AUTOSAR XML (schema 00051)
package /Components
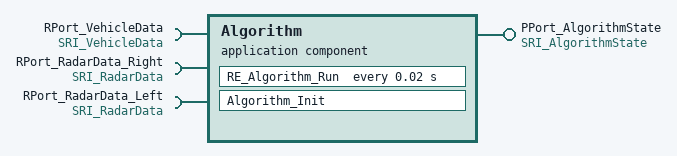
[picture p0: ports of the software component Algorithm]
  application sw component type Algorithm
    require port RPort_VehicleData: required-interface=SRI_VehicleData
      required-com-specs:
        data-element=TurnSignal_Status, init-value=SIGNAL_OK
        data-element=TurnSignal, init-value=TURN_OFF
        data-element=Vehicle_Speed, init-value=0
        data-element=Speed_Status, init-value=SIGNAL_OK
        data-element=Steering_Status, init-value=SIGNAL_OK
        data-element=Steering_Angle, init-value=0
        data-element=Gear_Status, init-value=SIGNAL_OK
        data-element=Gear, init-value=GEAR_PARK
    require port RPort_RadarData_Right: required-com-specs=[{data-element=Status, init-value=RADAR_OK}, {data-element=Distance, init-value=0}], required-interface=SRI_RadarData
    require port RPort_RadarData_Left: required-com-specs=[{data-element=Status, init-value=RADAR_OK}, {data-element=Distance, init-value=0}], required-interface=SRI_RadarData
    provide port PPort_AlgorithmState: provided-interface=SRI_AlgorithmState
      provided-com-specs:
        data-element=BSD_State_Right, init-value=BSD_CLEAR
        data-element=BSD_State_Left, init-value=BSD_CLEAR
    behavior Algorithm_IB: data-type-mapping=bsdDataTypeMappingsSet, handle-termination-and-restart=NO-SUPPORT
      timing event TE_Algorithm_20ms: start-on-event=RE_Algorithm_Run, period=0.02
      runnable Algorithm_Init
      runnable RE_Algorithm_Run
        data-read-access:
          6 x access:
            IN_RPort_RadarData_Right_Status: accessed-variable=RPort_RadarData_Right.Status
            IN_RPort_VehicleData_Speed_Status: accessed-variable=RPort_VehicleData.Speed_Status
            IN_RPort_RadarData_Right_Distance: accessed-variable=RPort_RadarData_Right.Distance
            IN_RPort_RadarData_Left_Distance: accessed-variable=RPort_RadarData_Left.Distance
            IN_RPort_RadarData_Left_Status: accessed-variable=RPort_RadarData_Left.Status
            IN_RPort_VehicleData_Vehicle_Speed: accessed-variable=RPort_VehicleData.Vehicle_Speed
        data-write-access:
          access OUT_PPort_AlgorithmState_BSD_State_Right: accessed-variable=PPort_AlgorithmState.BSD_State_Right
          access OUT_PPort_AlgorithmState_BSD_State_Left: accessed-variable=PPort_AlgorithmState.BSD_State_Left
